# RL6678_IP_SVD register map
Vendor: Realtek
Registers are 32-bit, read-write, reset 0x0 unless marked. A register's access mark holds for its fields unless they carry their own. Offsets are from the block's base; [hi:lo] are bit positions; <NAME> marks a mode.

## PSRAM_PHY_REG
Base 0x41002000
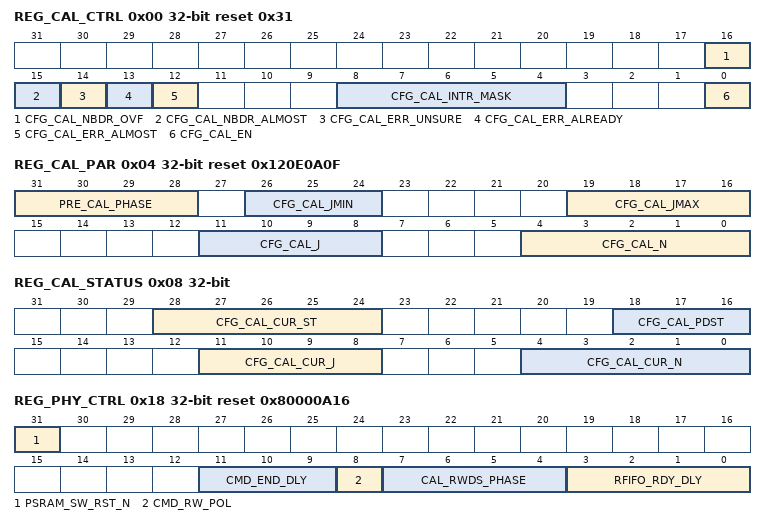
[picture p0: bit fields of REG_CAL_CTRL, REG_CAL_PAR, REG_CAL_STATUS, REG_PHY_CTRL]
0x00 REG_CAL_CTRL access per field reset 0x31
  [16] CFG_CAL_NBDR_OVF ro — The N reachs the boundary , which is 0 or Nmax . Cleared by write 1 .
  [15] CFG_CAL_NBDR_ALMOST ro — The N-J or N+J reachs the boundary , which is 0 or Nmax . Cleared by write 1 .
  [14] CFG_CAL_ERR_UNSURE ro — The Pre N/J may cause current burst receive error , but it is not sure because the burst len is too small. Cleared by write 1 .
  [13] CFG_CAL_ERR_ALREADY ro — The Pre N/J may cause current burst receive error , even change J to Jmin , the error still remain . Cleared by write 1 .
  [12] CFG_CAL_ERR_ALMOST ro — The current burst receive correct , but next burst will set J = Jmin . Cleared by write 1 .
  [8:4] CFG_CAL_INTR_MASK rw — Calibration fail interrupt mask , every bit control one event above (1: enable , 0: disable) [0] : err almost [1] : err already [2] : err unsure [3] : nbdr almost [4] : nbdr ovf
  [0] CFG_CAL_EN rw — Hardware auto calibration enable , if disable , N,J will be fixed .
0x04 REG_CAL_PAR reset 0x120E0A0F
  [31:28] PRE_CAL_PHASE — one-hot phase select, 4-tap delay line to adjust rwds phase before calibration for large freq range or skew can be set to 0, bypassing the default 1-tap delay
  [26:24] CFG_CAL_JMIN — Minimum J . Hardware may adjust J , if J reach this value , an interrup will be raised to alerm software.
  [19:16] CFG_CAL_JMAX — Maximum J . Hardware may adjust J , but will not exceed this value.
  [11:8] CFG_CAL_J — Initial value J calibrated by software .
  [4:0] CFG_CAL_N — Initial value N calibrated by software .
0x08 REG_CAL_STATUS ro
  [28:24] CFG_CAL_CUR_ST — Calibration current state . Cleared by write all 1 .
  [18:16] CFG_CAL_PDST — Calibration check result for last read burst . [0] : indicate phase n+j , if 1 , means dn == dn+j [1] : indicate phase n-j , if 1 , means dn == dn-j [2] : if 1 , means the state is under j = jmin condition
  [11:8] CFG_CAL_CUR_J — Current value J read from hardware.
  [4:0] CFG_CAL_CUR_N — Current value N read from hardware.
0x10 REG_CMD_INFO ro
  [7:0] CMD_INFO — Command information, 1st Byte of Command/Address transaction
0x18 REG_PHY_CTRL reset 0x80000A16
  [31] PSRAM_SW_RST_N — low active, except for phy register(using system reset), psram software reset: psram, phy_ctrl, calibration
  [11:9] CMD_END_DLY — delay required cycles(phy clk) after cmd end to bypass high-z DQS, must < (read_latency - 1)*2
  [8] CMD_RW_POL — polarity option for read/write bit in command, 0 for APM, 1 for winbond
  [7:4] CAL_RWDS_PHASE — one-hot phase select, delay cal_rwds to push sampling data into rfifo
  [3:0] RFIFO_RDY_DLY — delay read data cycles(phy clk) from psram to controller, must >= 6
0x80 REG_DDR_PAD_CTRL0 reset 0x9A6
  [26:0] dq_ctrl_psram
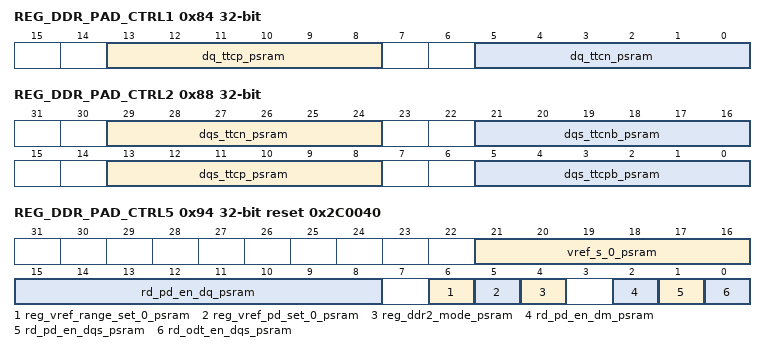
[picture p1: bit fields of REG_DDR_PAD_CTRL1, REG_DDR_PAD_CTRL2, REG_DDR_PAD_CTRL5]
0x84 REG_DDR_PAD_CTRL1
  [13:8] dq_ttcp_psram, [5:0] dq_ttcn_psram
0x88 REG_DDR_PAD_CTRL2
  [29:24] dqs_ttcn_psram, [21:16] dqs_ttcnb_psram, [13:8] dqs_ttcp_psram, [5:0] dqs_ttcpb_psram
0x8C REG_DDR_PAD_CTRL3 reset 0x9A6
  [11:0] dqs_n_ctrl_psram
0x90 REG_DDR_PAD_CTRL4 reset 0x9A6
  [27:0] dqs_p_ctrl_psram
0x94 REG_DDR_PAD_CTRL5 reset 0x2C0040
  [21:16] vref_s_0_psram, [15:8] rd_pd_en_dq_psram, [6] reg_vref_range_set_0_psram, [5] reg_vref_pd_set_0_psram, [4] reg_ddr2_mode_psram, [2] rd_pd_en_dm_psram, [1] rd_pd_en_dqs_psram, [0] rd_odt_en_dqs_psram
0xF0 REG_DBG_SEL
  [7:0] PSRAM_PHY_DBG_SEL — psram phy debug select signal.
0xF8 REG_DBG_INFO ro
  [31:0] PSRAM_PHY_DBG — psram phy debug signals.

## DBGTIM_REG
Base 0x42009000
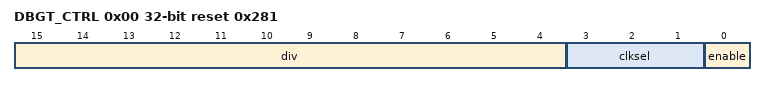
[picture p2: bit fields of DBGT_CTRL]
0x00 DBGT_CTRL reset 0x281 — debugtimer control register
  [15:4] div — The default value can used to divide 40M Xtal to 1M
  [3:1] clksel — Clock source select 1: Select 32K as clock source. 0: Select Xtal as clock source. 2~7: Reserved
  [0] enable — Debug timer enable. 1: The counter is enabled. 0: The counter is disabled.
0x04 DBGT_CRV wo — debugtimer count register
  [31:0] dbgt_crv — Continuing to count from 0 once it's reached 32'hFFFFFFFF
0x08 DBGT_ATOM_INC ro — debugtimer atom read increase
  [31:0] dbgt_atom_inc — Each read will increase 1 and return to the increased value to bus.
0x0C DBGT_ATOM wo — debugtimer atom
  [31:0] dbgt_atom — Return the last increased value of atom counter
0x10 DBGT_SCRATCH — debugtimer scratch
  [31:0] dbgt_scratch — Reserved for user use

## WDG0_REG
Base 0x42008400
Same registers: WDG2_REG 0x41000440, WDG4_REG 0x410004C0, WDG1_REG_S 0x51000400, WDG3_REG_S 0x51000480
0x00 WDG_MKEYR — WDG Magic Key register
  [15:0] MKEY — 0x6969: enable access to register WDG_CR/WDG_RLR/WDG_WINR 0x5A5A: reload WDG counter 0x3C3C: enable WDG function
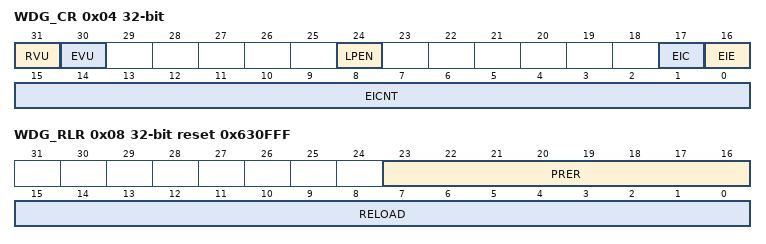
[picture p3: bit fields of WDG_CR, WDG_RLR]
0x04 WDG_CR access per field — WDG Control regsietr
  [31] RVU ro — Watchdog counter update by reload command
  [30] EVU ro — Watchdog early interrupt function update
  [24] LPEN rw — Low power enable 0: WDG will gating when system goes into sleep mode 1: WDG keep running when system goes into sleep mode
  [17] EIC wo — Write '1' clear the early interrupt
  [16] EIE rw — Watchdog early interrupt enable
  [15:0] EICNT rw — Early interrupt trigger threshold
0x08 WDG_RLR reset 0x630FFF — WDG Relaod register
  [23:16] PRER — Prescaler counter, configuration only allowed before wdg enable WDG: 0x63 System wdg: 0x1F
  [15:0] RELOAD — Reload value for watchdog counter
0x0C WDG_WINR reset 0xFFFF — WDG Window Register
  [15:0] WINDOW — Watchdog feed protect window register

## RSA_REG
Base 0x400EB000
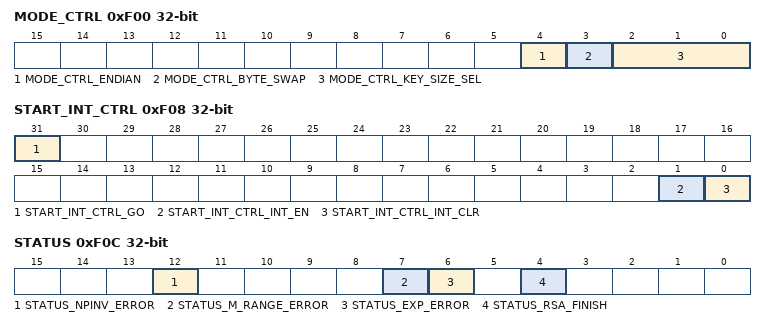
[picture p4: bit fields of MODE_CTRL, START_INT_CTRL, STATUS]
0xF00 MODE_CTRL ro — Mode Control Register
  [4] MODE_CTRL_ENDIAN — 0x0: little 0x1: big
  [3] MODE_CTRL_BYTE_SWAP — Byte swapping in a word 0x0: little 0x1: big
  [2:0] MODE_CTRL_KEY_SIZE_SEL — 0x0: 2048 0x2: 1024 0x5: 3072
0xF08 START_INT_CTRL ro — Start Interrupt Control Register
  [31] START_INT_CTRL_GO — Write 1 to start engine
  [1] START_INT_CTRL_INT_EN — Interrupt enable
  [0] START_INT_CTRL_INT_CLR — 0x0: no interrupt 0x1: interrupt active Write 1 to clear interrupt
0xF0C STATUS ro
  [12] STATUS_NPINV_ERROR — NPINV generate error (modular is not odd)
  [7] STATUS_M_RANGE_ERROR — M > N error
  [6] STATUS_EXP_ERROR — Exponent error (exponent is all zero)
  [4] STATUS_RSA_FINISH — RSA finish
0xF2C CLK_GATING_CTRL ro reset 0x1 — Clock Gating Control Register
  [0] LCLK_GATING_CTRL_EN — Auto clock gating enable

## PAGE26
Base 0x40000000
0x2600 TWT_BC_ID — TWT IE ID BITMAP
  [31:0] r_BC_TWT_ID — TWT ID bitmap, each bit corresponding to a ID value
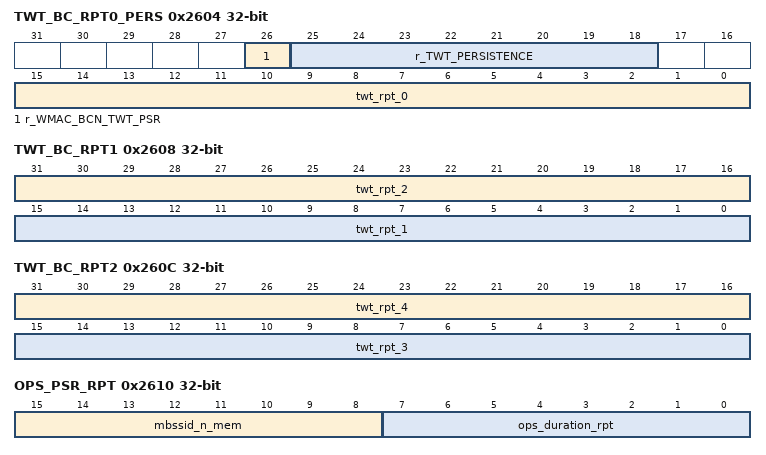
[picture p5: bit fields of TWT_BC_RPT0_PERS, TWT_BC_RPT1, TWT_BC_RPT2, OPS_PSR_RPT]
0x2604 TWT_BC_RPT0_PERS — TWT IE persistence reference and RPT0
  [26] r_WMAC_BCN_TWT_PSR — enable bcn twt bc ie parser
  [25:18] r_TWT_PERSISTENCE — persistence vlaue, if persistence value in TWT IE is smaller than the reference, bcnpsf will lat the twt id rpt
  [15:0] twt_rpt_0 — specified twt id report
0x2608 TWT_BC_RPT1 — TWT IE ID RPT1
  [31:16] twt_rpt_2 — specified twt id report
  [15:0] twt_rpt_1 — specified twt id report
0x260C TWT_BC_RPT2 — TWT IE ID RPT2
  [31:16] twt_rpt_4 — specified twt id report
  [15:0] twt_rpt_3 — specified twt id report
0x2610 OPS_PSR_RPT — OPS DURATION
  [15:8] mbssid_n_mem — multi-bssid n value
  [7:0] ops_duration_rpt — ops frame duration field rpt
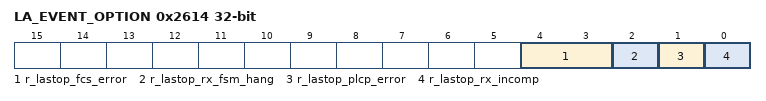
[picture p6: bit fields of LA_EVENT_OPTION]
0x2614 LA_EVENT_OPTION
  [4:3] r_lastop_fcs_error — stop LA record when continue fcs error >= threshold 0:disable 1:4 2:8 3:12
  [2] r_lastop_rx_fsm_hang — stop LA record when RX FSM timeout
  [1] r_lastop_plcp_error — stop LA record when RX PLCP error occur, include Length error, parity error or crc error
  [0] r_lastop_rx_incomp — stop LA record when RX content is incompleted, include PLCP is incompleted or PSDU is incompleted
0x2618 RESP_AID_11 — aid 11 for resp
  [10:0] aid11 — specified the aid of the sta that mactx responding to
